# nrf9120_mlm1_modem register map
Vendor: Nordic Semiconductor; Series: nrf91; File version: 1
CPU: CM4 r0p1, little endian, MPU, no FPU, 3 interrupt priority bits
Registers are 32-bit, read-write, reset 0x0 unless marked. A register's access mark holds for its fields unless they carry their own. Offsets are from the block's base; [hi:lo] are bit positions; {n}, {i} and the like mark numbered series; 'fields as' and 'values as' point back to an identical list.

## DESCIPHER — DES HW Accelerator
Base 0x40052000
0x00 TASKS_START_GATHER wo — Start input DMA
  [0] TASKS_START_GATHER
    1=Trigger task
0x04 TASKS_STOP_GATHER wo — Stop input DMA
  [0] TASKS_STOP_GATHER
    1=Trigger task
0x08 TASKS_START_SCATTER wo — Start output DMA
  [0] TASKS_START_SCATTER
    1=Trigger task
0x0C TASKS_STOP_SCATTER wo — Stop output DMA
  [0] TASKS_STOP_SCATTER
    1=Trigger task
0x10 TASKS_INITIALIZE_DES wo — New keys (and IV) ready to be used, reset keybytes, ivbytes
  [0] TASKS_INITIALIZE_DES
    1=Trigger task
0x14 TASKS_FILL_DES_INPUT wo — Transfer 8 bytes of input from DMA to DES core
  [0] TASKS_FILL_DES_INPUT
    1=Trigger task
0x18 TASKS_DES_ENCRYPT_1 wo — Starts DES encryption with keyset 1 ( input -> output)
  [0] TASKS_DES_ENCRYPT_1
    1=Trigger task
0x1C TASKS_DES_DECRYPT_1 wo — Starts DES decryption with keyset 1 ( input -> output)
  [0] TASKS_DES_DECRYPT_1
    1=Trigger task
0x20 TASKS_DES_ENCRYPT_2 wo — Starts DES encryption with keyset 2 (output -> output)
  [0] TASKS_DES_ENCRYPT_2
    1=Trigger task
0x24 TASKS_DES_DECRYPT_2 wo — Starts DES decryption with keyset 2 (output -> output)
  [0] TASKS_DES_DECRYPT_2
    1=Trigger task
0x28 TASKS_DES_ENCRYPT_3 wo — Starts DES encryption with keyset 3 (output -> output)
  [0] TASKS_DES_ENCRYPT_3
    1=Trigger task
0x2C TASKS_DES_DECRYPT_3 wo — Starts DES decryption with keyset 3 (output -> output)
  [0] TASKS_DES_DECRYPT_3
    1=Trigger task
0x30 TASKS_DRAIN_DES_OUTPUT wo — Transfer 8 bytes of output from DES core to DMA
  [0] TASKS_DRAIN_DES_OUTPUT
    1=Trigger task
0x34 TASKS_RESET wo — Stop all transfers and crypto operations (software reset)
  [0] TASKS_RESET
    1=Trigger task
0x70 TASKZEROPENALTY_PCP_1 wo — TaskZeroPenalty register for PCP 1
  [0] ZERO_PENALTY
    1=SET_ZERO_PENALTY
0x74 TASKFULLPENALTY_PCP_1 wo — TaskFullPenalty register for PCP 1
  [0] FULL_PENALTY
    1=SET_FULL_PENALTY
0x78 TASKZEROPENALTY_PCP_0 wo — TaskZeroPenalty register for PCP 0
  [0] ZERO_PENALTY
    1=SET_ZERO_PENALTY
0x7C TASKFULLPENALTY_PCP_0 wo — TaskFullPenalty register for PCP 0
  [0] FULL_PENALTY
    1=SET_FULL_PENALTY
0x100 EVENTS_GATHER_STARTED — Input DMA started
  [0] EVENTS_GATHER_STARTED
    0=NotGenerated (Event not generated); 1=Generated (Event generated)
0x104 EVENTS_GATHER_DONE — Input DMA done
  [0] EVENTS_GATHER_DONE
    values as EVENTS_GATHER_STARTED.EVENTS_GATHER_STARTED
0x108 EVENTS_SCATTER_STARTED — Output DMA started
  [0] EVENTS_SCATTER_STARTED
    values as EVENTS_GATHER_STARTED.EVENTS_GATHER_STARTED
0x10C EVENTS_SCATTER_DONE — Output DMA done
  [0] EVENTS_SCATTER_DONE
    values as EVENTS_GATHER_STARTED.EVENTS_GATHER_STARTED
0x110 EVENTS_KEY_1_READY — Key #1 received (keybytes == 8)
  [0] EVENTS_KEY_1_READY
    values as EVENTS_GATHER_STARTED.EVENTS_GATHER_STARTED
0x114 EVENTS_KEY_3_READY — Keys #1, #2 and #3 received (keybytes == 24)
  [0] EVENTS_KEY_3_READY
    values as EVENTS_GATHER_STARTED.EVENTS_GATHER_STARTED
0x118 EVENTS_IV_READY — IV received (ivbytes == 8)
  [0] EVENTS_IV_READY
    values as EVENTS_GATHER_STARTED.EVENTS_GATHER_STARTED
0x11C EVENTS_DES_INITIALIZED — New keys (and IV) taken into use
  [0] EVENTS_DES_INITIALIZED
    values as EVENTS_GATHER_STARTED.EVENTS_GATHER_STARTED
0x120 EVENTS_DES_INPUT_FULL — 8 bytes of input stored to DES core
  [0] EVENTS_DES_INPUT_FULL
    values as EVENTS_GATHER_STARTED.EVENTS_GATHER_STARTED
{0x120+4i} EVENTS_DES_DONE_{i} (i=1..3) — Action with key {i} ready
  [0] EVENTS_DES_DONE_{i}
    values as EVENTS_GATHER_STARTED.EVENTS_GATHER_STARTED
0x130 EVENTS_DES_OUTPUT_EMPTY — 8 bytes of output read from DES core
  [0] EVENTS_DES_OUTPUT_EMPTY
    values as EVENTS_GATHER_STARTED.EVENTS_GATHER_STARTED
0x134 EVENTS_MESSAGE_READY — LENGTH == 0, message processed
  [0] EVENTS_MESSAGE_READY
    values as EVENTS_GATHER_STARTED.EVENTS_GATHER_STARTED
0x138 EVENTS_RESETTED — Resetted (all transfers and crypto operations stopped)
  [0] EVENTS_RESETTED
    values as EVENTS_GATHER_STARTED.EVENTS_GATHER_STARTED
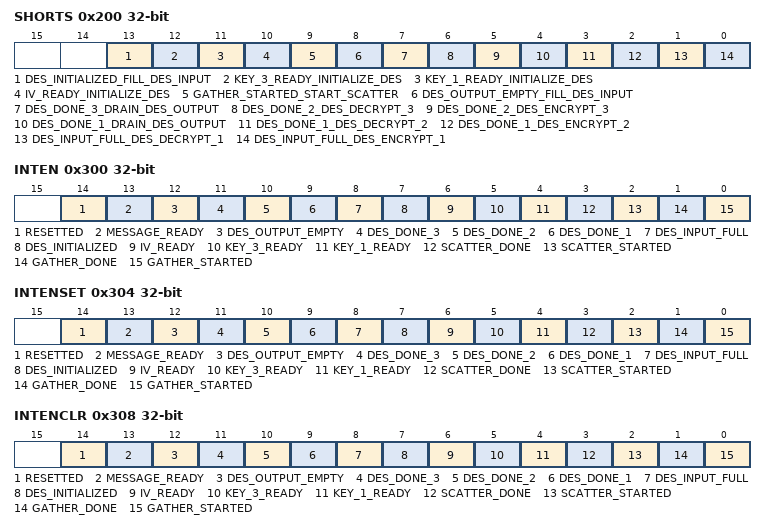
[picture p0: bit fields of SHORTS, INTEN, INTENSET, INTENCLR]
0x200 SHORTS — Shortcuts between local events and tasks
  [all] fields
    0=Disabled (Disable shortcut); 1=Enabled (Enable shortcut)
  [13] DES_INITIALIZED_FILL_DES_INPUT — Shortcut between event DES_INITIALIZED and task FILL_DES_INPUT
  [12] KEY_3_READY_INITIALIZE_DES — Shortcut between event KEY_3_READY and task INITIALIZE_DES
  [11] KEY_1_READY_INITIALIZE_DES — Shortcut between event KEY_1_READY and task INITIALIZE_DES
  [10] IV_READY_INITIALIZE_DES — Shortcut between event IV_READY and task INITIALIZE_DES
  [9] GATHER_STARTED_START_SCATTER — Shortcut between event GATHER_STARTED and task START_SCATTER
  [8] DES_OUTPUT_EMPTY_FILL_DES_INPUT — Shortcut between event DES_OUTPUT_EMPTY and task FILL_DES_INPUT
  [7] DES_DONE_3_DRAIN_DES_OUTPUT — Shortcut between event DES_DONE_3 and task DRAIN_DES_OUTPUT
  [6] DES_DONE_2_DES_DECRYPT_3 — Shortcut between event DES_DONE_2 and task DES_DECRYPT_3
  [5] DES_DONE_2_DES_ENCRYPT_3 — Shortcut between event DES_DONE_2 and task DES_ENCRYPT_3
  [4] DES_DONE_1_DRAIN_DES_OUTPUT — Shortcut between event DES_DONE_1 and task DRAIN_DES_OUTPUT
  [3] DES_DONE_1_DES_DECRYPT_2 — Shortcut between event DES_DONE_1 and task DES_DECRYPT_2
  [2] DES_DONE_1_DES_ENCRYPT_2 — Shortcut between event DES_DONE_1 and task DES_ENCRYPT_2
  [1] DES_INPUT_FULL_DES_DECRYPT_1 — Shortcut between event DES_INPUT_FULL and task DES_DECRYPT_1
  [0] DES_INPUT_FULL_DES_ENCRYPT_1 — Shortcut between event DES_INPUT_FULL and task DES_ENCRYPT_1
0x300 INTEN — Enable or disable interrupt
  [all] fields
    0=Disabled; 1=Enabled
  [14] RESETTED — Enable or disable interrupt for event RESETTED
  [13] MESSAGE_READY — Enable or disable interrupt for event MESSAGE_READY
  [12] DES_OUTPUT_EMPTY — Enable or disable interrupt for event DES_OUTPUT_EMPTY
  [11] DES_DONE_3 — Enable or disable interrupt for event DES_DONE_3
  [10] DES_DONE_2 — Enable or disable interrupt for event DES_DONE_2
  [9] DES_DONE_1 — Enable or disable interrupt for event DES_DONE_1
  [8] DES_INPUT_FULL — Enable or disable interrupt for event DES_INPUT_FULL
  [7] DES_INITIALIZED — Enable or disable interrupt for event DES_INITIALIZED
  [6] IV_READY — Enable or disable interrupt for event IV_READY
  [5] KEY_3_READY — Enable or disable interrupt for event KEY_3_READY
  [4] KEY_1_READY — Enable or disable interrupt for event KEY_1_READY
  [3] SCATTER_DONE — Enable or disable interrupt for event SCATTER_DONE
  [2] SCATTER_STARTED — Enable or disable interrupt for event SCATTER_STARTED
  [1] GATHER_DONE — Enable or disable interrupt for event GATHER_DONE
  [0] GATHER_STARTED — Enable or disable interrupt for event GATHER_STARTED
0x304 INTENSET — Enable interrupt
  [all] fields
    on read: 0=Disabled (Read: Disabled); 1=Enabled (Read: Enabled) | on write: 1=Set (Enable)
  [14] RESETTED — Write '1' to enable interrupt for event RESETTED
  [13] MESSAGE_READY — Write '1' to enable interrupt for event MESSAGE_READY
  [12] DES_OUTPUT_EMPTY — Write '1' to enable interrupt for event DES_OUTPUT_EMPTY
  [11] DES_DONE_3 — Write '1' to enable interrupt for event DES_DONE_3
  [10] DES_DONE_2 — Write '1' to enable interrupt for event DES_DONE_2
  [9] DES_DONE_1 — Write '1' to enable interrupt for event DES_DONE_1
  [8] DES_INPUT_FULL — Write '1' to enable interrupt for event DES_INPUT_FULL
  [7] DES_INITIALIZED — Write '1' to enable interrupt for event DES_INITIALIZED
  [6] IV_READY — Write '1' to enable interrupt for event IV_READY
  [5] KEY_3_READY — Write '1' to enable interrupt for event KEY_3_READY
  [4] KEY_1_READY — Write '1' to enable interrupt for event KEY_1_READY
  [3] SCATTER_DONE — Write '1' to enable interrupt for event SCATTER_DONE
  [2] SCATTER_STARTED — Write '1' to enable interrupt for event SCATTER_STARTED
  [1] GATHER_DONE — Write '1' to enable interrupt for event GATHER_DONE
  [0] GATHER_STARTED — Write '1' to enable interrupt for event GATHER_STARTED
0x308 INTENCLR — Disable interrupt
  [all] fields
    on read: 0=Disabled (Read: Disabled); 1=Enabled (Read: Enabled) | on write: 1=Clear (Disable)
  [14] RESETTED — Write '1' to disable interrupt for event RESETTED
  [13] MESSAGE_READY — Write '1' to disable interrupt for event MESSAGE_READY
  [12] DES_OUTPUT_EMPTY — Write '1' to disable interrupt for event DES_OUTPUT_EMPTY
  [11] DES_DONE_3 — Write '1' to disable interrupt for event DES_DONE_3
  [10] DES_DONE_2 — Write '1' to disable interrupt for event DES_DONE_2
  [9] DES_DONE_1 — Write '1' to disable interrupt for event DES_DONE_1
  [8] DES_INPUT_FULL — Write '1' to disable interrupt for event DES_INPUT_FULL
  [7] DES_INITIALIZED — Write '1' to disable interrupt for event DES_INITIALIZED
  [6] IV_READY — Write '1' to disable interrupt for event IV_READY
  [5] KEY_3_READY — Write '1' to disable interrupt for event KEY_3_READY
  [4] KEY_1_READY — Write '1' to disable interrupt for event KEY_1_READY
  [3] SCATTER_DONE — Write '1' to disable interrupt for event SCATTER_DONE
  [2] SCATTER_STARTED — Write '1' to disable interrupt for event SCATTER_STARTED
  [1] GATHER_DONE — Write '1' to disable interrupt for event GATHER_DONE
  [0] GATHER_STARTED — Write '1' to disable interrupt for event GATHER_STARTED
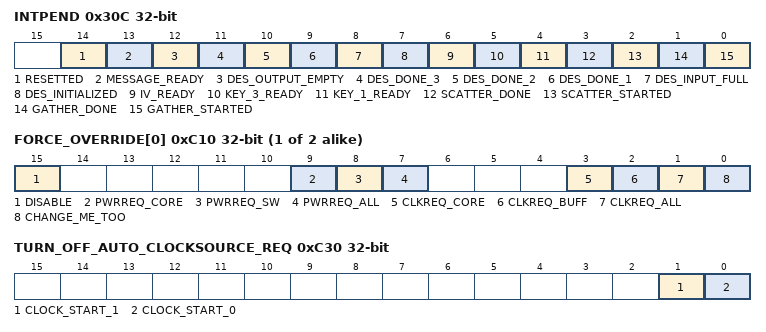
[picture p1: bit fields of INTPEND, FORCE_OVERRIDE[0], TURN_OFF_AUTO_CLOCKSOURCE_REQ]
0x30C INTPEND ro — Pending interrupts
  [all] fields
    on read: 0=NotPending (Read: Not pending); 1=Pending (Read: Pending)
  [14] RESETTED — Read pending status of interrupt for event RESETTED
  [13] MESSAGE_READY — Read pending status of interrupt for event MESSAGE_READY
  [12] DES_OUTPUT_EMPTY — Read pending status of interrupt for event DES_OUTPUT_EMPTY
  [11] DES_DONE_3 — Read pending status of interrupt for event DES_DONE_3
  [10] DES_DONE_2 — Read pending status of interrupt for event DES_DONE_2
  [9] DES_DONE_1 — Read pending status of interrupt for event DES_DONE_1
  [8] DES_INPUT_FULL — Read pending status of interrupt for event DES_INPUT_FULL
  [7] DES_INITIALIZED — Read pending status of interrupt for event DES_INITIALIZED
  [6] IV_READY — Read pending status of interrupt for event IV_READY
  [5] KEY_3_READY — Read pending status of interrupt for event KEY_3_READY
  [4] KEY_1_READY — Read pending status of interrupt for event KEY_1_READY
  [3] SCATTER_DONE — Read pending status of interrupt for event SCATTER_DONE
  [2] SCATTER_STARTED — Read pending status of interrupt for event SCATTER_STARTED
  [1] GATHER_DONE — Read pending status of interrupt for event GATHER_DONE
  [0] GATHER_STARTED — Read pending status of interrupt for event GATHER_STARTED
0x400 LENGTH — Data length in bytes
0x404 MODE — Mode: 0 == ECB, 1 == CBC
  [0] MODE — Selects ECB or CBC block cipher mode
    0=ECB (Electronic Codebook mode); 1=CBC (Cipher Block Chaining mode)
0x500 ENABLE — Enable/disable block
  [0] ENABLE — Enable or disable DES module
    0=Disabled; 1=Enabled
0x800 INJOBPTR — Input DMA job pointer register
  [31:0] INJOBPTR — Input DMA job pointer
0x900 OUTJOBPTR — Output DMA job pointer register
  [31:0] OUTJOBPTR — Output DMA job pointer
{0xC00+4i} PENALTY_REG[{i}] (i=0..1) — Description collection: Penalty register for PCP n
  [1:0] PENALTY — Penalty Level
    0=Full (Auto 0) Full penalty)); 1=Semi1 ((Auto 1) Semi (power on, clock off)); 2=Semi0 ((Auto 2) Semi (power on, clock core on, clock buffer off)); 3=Zero ((Auto 3) Zero penalty)
{0xC10+4i} FORCE_OVERRIDE[{i}] (i=0..1) — Description collection: Force override register for PCP n
  [15] DISABLE
    0=Zero (all forcing disabled); 1=One (all forcing enabled)
  [9] PWRREQ_CORE
    0=Zero (powerRequest.core = 0); 1=One (powerRequest.core = 1)
  [8] PWRREQ_SW
    0=Zero (powerRequest.switch = 0); 1=One (powerRequest.switch = 1)
  [7] PWRREQ_ALL
    0=Zero (All clock forcing disabled); 1=One (All clock forcing enabled)
  [3] CLKREQ_CORE
    0=Zero (clockRequest.core = 0); 1=One (clockRequest.core = 1)
  [2] CLKREQ_BUFF
    0=Zero (clockRequest.buff = 0); 1=One (clockRequest.buff = 1)
  [1] CLKREQ_ALL
    0=Zero (clockRequest.switch = 0); 1=One (clockRequest.switch = 1)
  [0] CHANGE_ME_TOO
    0=Zero (clockRequest.switch_a = 0); 1=One (clockRequest.switch_a = 1)
0xC30 TURN_OFF_AUTO_CLOCKSOURCE_REQ — Turn of the automatic clock request.
  [1] CLOCK_START_1
    0=Zero (normal clock start for PCP 1); 1=One (turn off normal clock start for PCP 1)
  [0] CLOCK_START_0
    0=Zero (normal clock start for PCP 0); 1=One (turn off normal clock start for PCP 0)
